# SA3_SS0_RINGACC_0_IPCSS_RINGACC_CFG_GCFG register map
Vendor: Texas Instruments
Peripheral module from a debugger description file (folder am62P).
Registers are 32-bit, read-write, reset 0x0 unless marked. A register's access mark holds for its fields unless they carry their own. Offsets are as the file gives them; lines under a group give offsets from that group; [hi:lo] are bit positions; {n}, {i} and the like mark numbered series; 'fields as' and 'values as' point back to an identical list; <NAME> marks a mode.

## SA3_SS0_RINGACC_0_IPCSS_RINGACC_CFG_GCFG
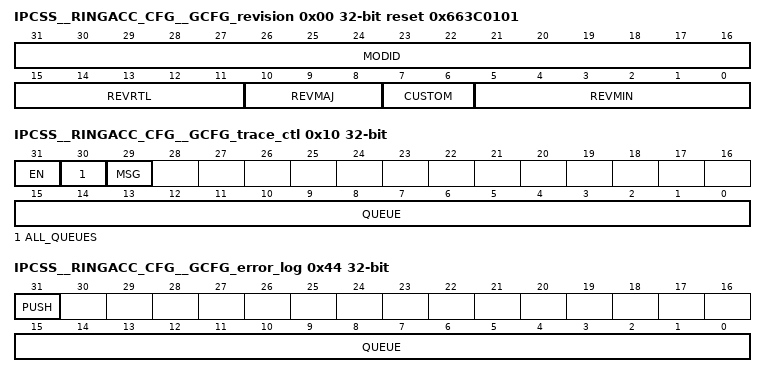
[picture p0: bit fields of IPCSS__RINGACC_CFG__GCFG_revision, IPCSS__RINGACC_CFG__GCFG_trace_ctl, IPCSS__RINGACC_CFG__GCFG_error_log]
0x00 IPCSS__RINGACC_CFG__GCFG_revision ro reset 0x663C0101 — The Revision Register contains the major and minor revisions for the module.
  [31:16] MODID — Module ID field
  [15:11] REVRTL — RTL revision. Will vary depending on release.
  [10:8] REVMAJ — Major revision
  [7:6] CUSTOM
  [5:0] REVMIN — Minor revision
0x10 IPCSS__RINGACC_CFG__GCFG_trace_ctl — Trace Control Register
  [31] EN — Trace enable 0 = disable 1 = enable.
  [30] ALL_QUEUES — Trace everything 0 = only the selected queue 1 = every queue.
  [29] MSG — Trace message data 0 = include only the operation 1 = include message data.
  [15:0] QUEUE — Queue number when tracing a single queue.
0x20 IPCSS__RINGACC_CFG__GCFG_overflow — Overflow Queue Register
  [15:0] QUEUE — Queue to send overflow messages. A value of 0xffff will disable the overflow function.
0x40 IPCSS__RINGACC_CFG__GCFG_error_evt reset 0xFFFF — The Error Event Register is an Output Event Steering 'OES' register that specifies the event number used to denote detection of a ring memory transaction bus error.
  [15:0] EVT — Event to send when detecting a bus error.
0x44 IPCSS__RINGACC_CFG__GCFG_error_log ro — Error Log Register. A read of this register will clear the pending error log event and allow a new error to be captured. It does not clear the contents of this register which are only valid while the error event is pending.
  [31] PUSH — Bus error was caused by a push. 0 = pop. 1 = push.
  [15:0] QUEUE — Queue that received the bus error.
